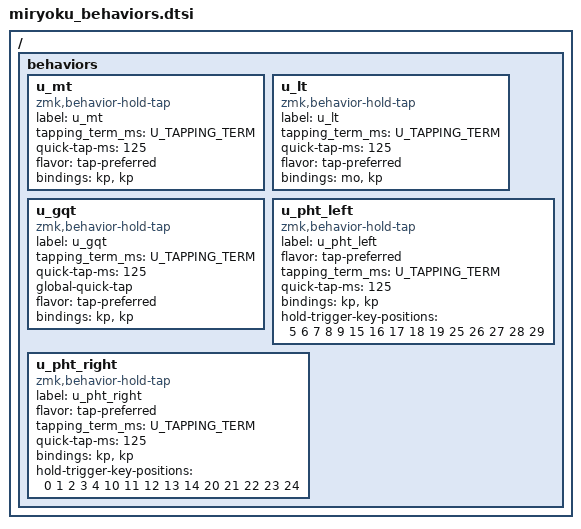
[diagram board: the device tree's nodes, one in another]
// Copyright 2022 Manna Harbour
// https://github.com/manna-harbour/miryoku

/ {
  behaviors {
    u_mt: u_mt {
      compatible = "zmk,behavior-hold-tap";
      label = "u_mt";
      #binding-cells = <2>;
      tapping_term_ms = <U_TAPPING_TERM>;
      quick-tap-ms = <125>; // MY MODIFICATION
      flavor = "tap-preferred";
      bindings = <&kp>, <&kp>;
    };
    u_lt: u_lt {
      compatible = "zmk,behavior-hold-tap";
      label = "u_lt";
      #binding-cells = <2>;
      tapping_term_ms = <U_TAPPING_TERM>;
      quick-tap-ms = <125>; // MY MODIFICATION
      flavor = "tap-preferred";
      bindings = <&mo>, <&kp>;
    };

    // MY MODIFICATIONS:
    u_gqt: u_gqt {
      compatible = "zmk,behavior-hold-tap";
      label = "u_gqt";
      #binding-cells = <2>;
      tapping_term_ms = <U_TAPPING_TERM>;
      quick-tap-ms = <125>;
      global-quick-tap;
      flavor = "tap-preferred";
      bindings = <&kp>, <&kp>;
    };
    u_pht_left: u_pht_left {
      compatible = "zmk,behavior-hold-tap";
      label = "u_pht_left";
      #binding-cells = <2>;
      flavor = "tap-preferred";
      tapping_term_ms = <U_TAPPING_TERM>;
      quick-tap-ms = <125>;
      bindings = <&kp>, <&kp>;
      hold-trigger-key-positions = <5 6 7 8 9 15 16 17 18 19 25 26 27 28 29>;
    };
    u_pht_right: u_pht_right {
      compatible = "zmk,behavior-hold-tap";
      label = "u_pht_right";
      #binding-cells = <2>;
      flavor = "tap-preferred";
      tapping_term_ms = <U_TAPPING_TERM>;
      quick-tap-ms = <125>;
      bindings = <&kp>, <&kp>;
      hold-trigger-key-positions = <0 1 2 3 4 10 11 12 13 14 20 21 22 23 24>;
    };
  };
};
